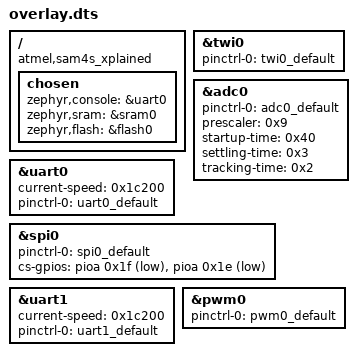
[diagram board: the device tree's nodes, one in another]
/ {
	compatible = "atmel,sam4s_xplained", "atmel,sam4s16c", "atmel,sam4s";
	chosen {
		zephyr,console = &uart0;
		zephyr,sram = &sram0;
		zephyr,flash = &flash0;
	};
};
&twi0{
	status = "okay";
	pinctrl-0 = < &twi0_default >;
	pinctrl-names = "default";
};
&adc0{
	status = "okay";
	pinctrl-0 = < &adc0_default >;
	pinctrl-names = "default";
	prescaler = < 0x9 >;
	startup-time = < 0x40 >;
	settling-time = < 0x3 >;
	tracking-time = < 0x2 >;
};
&uart0{
	status = "okay";
	current-speed = < 0x1c200 >;
	pinctrl-0 = < &uart0_default >;
	pinctrl-names = "default";
};
&spi0{
	status = "okay";
	pinctrl-0 = < &spi0_default >;
	pinctrl-names = "default";
	cs-gpios = < &pioa 0x1f 0x1 >, < &pioa 0x1e 0x1 >;
};
&uart1{
	status = "okay";
	current-speed = < 0x1c200 >;
	pinctrl-0 = < &uart1_default >;
	pinctrl-names = "default";
};
&pwm0{
	status = "okay";
	pinctrl-0 = < &pwm0_default >;
	pinctrl-names = "default";
};
